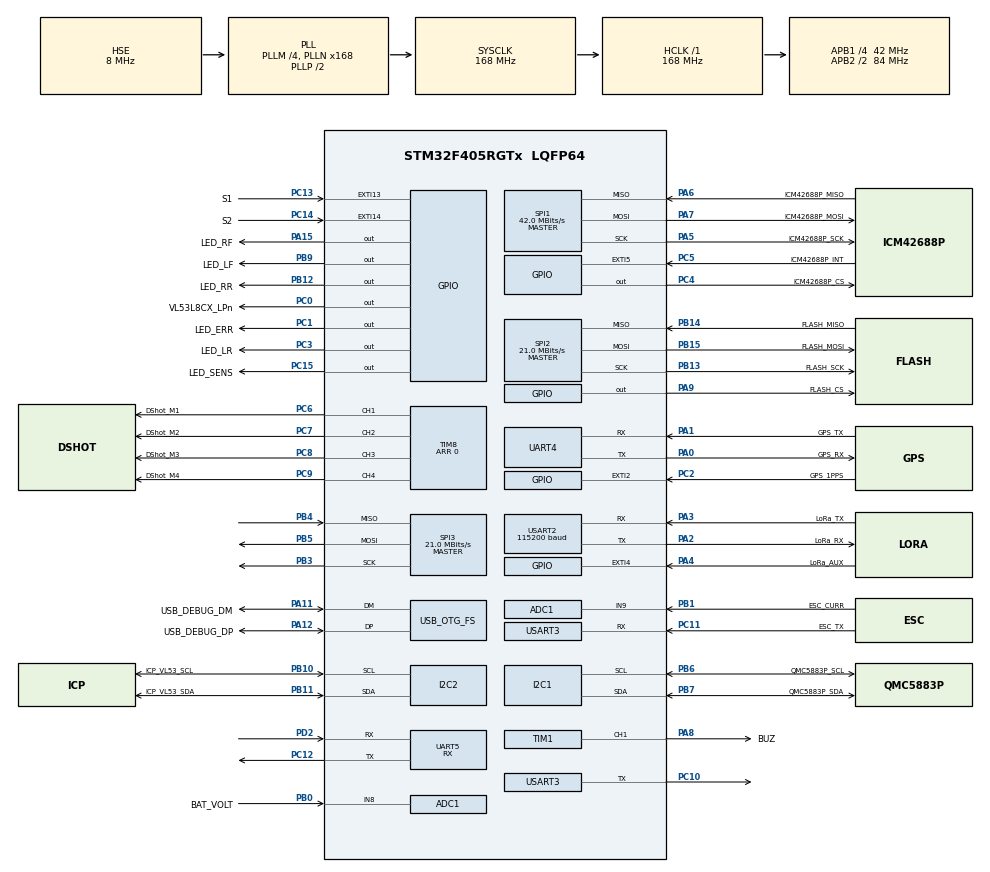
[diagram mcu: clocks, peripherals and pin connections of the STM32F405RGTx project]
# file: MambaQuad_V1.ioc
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ADC1.Channel-0\#ChannelRegularConversion=ADC_CHANNEL_8
ADC1.NbrOfConversionFlag=1
ADC1.Rank-0\#ChannelRegularConversion=1
ADC1.SamplingTime-0\#ChannelRegularConversion=ADC_SAMPLETIME_3CYCLES
ADC1.master=1
Dma.Request0=TIM8_CH1
Dma.Request1=TIM8_CH2
Dma.Request2=TIM8_CH3
Dma.Request3=TIM8_CH4/TRIG/COM
Dma.Request4=UART4_RX
Dma.Request5=UART5_RX
Dma.Request6=USART2_RX
Dma.Request7=USART3_RX
Dma.TIM8_CH1.0.Direction=DMA_MEMORY_TO_PERIPH
Dma.TIM8_CH1.0.FIFOMode=DMA_FIFOMODE_ENABLE
Dma.TIM8_CH1.0.FIFOThreshold=DMA_FIFO_THRESHOLD_1QUARTERFULL
Dma.TIM8_CH1.0.Instance=DMA2_Stream2
Dma.TIM8_CH1.0.MemBurst=DMA_MBURST_SINGLE
Dma.TIM8_CH1.0.MemDataAlignment=DMA_MDATAALIGN_WORD
Dma.TIM8_CH1.0.MemInc=DMA_MINC_ENABLE
Dma.TIM8_CH1.0.Mode=DMA_NORMAL
Dma.TIM8_CH1.0.PeriphBurst=DMA_PBURST_SINGLE
Dma.TIM8_CH1.0.PeriphDataAlignment=DMA_PDATAALIGN_WORD
Dma.TIM8_CH1.0.PeriphInc=DMA_PINC_DISABLE
Dma.TIM8_CH1.0.Priority=DMA_PRIORITY_HIGH
Dma.TIM8_CH2.1.Direction=DMA_MEMORY_TO_PERIPH
Dma.TIM8_CH2.1.FIFOMode=DMA_FIFOMODE_ENABLE
Dma.TIM8_CH2.1.FIFOThreshold=DMA_FIFO_THRESHOLD_1QUARTERFULL
Dma.TIM8_CH2.1.Instance=DMA2_Stream3
Dma.TIM8_CH2.1.MemBurst=DMA_MBURST_SINGLE
Dma.TIM8_CH2.1.MemDataAlignment=DMA_MDATAALIGN_WORD
Dma.TIM8_CH2.1.MemInc=DMA_MINC_ENABLE
Dma.TIM8_CH2.1.Mode=DMA_NORMAL
Dma.TIM8_CH2.1.PeriphBurst=DMA_PBURST_SINGLE
Dma.TIM8_CH2.1.PeriphDataAlignment=DMA_PDATAALIGN_WORD
Dma.TIM8_CH2.1.PeriphInc=DMA_PINC_DISABLE
Dma.TIM8_CH2.1.Priority=DMA_PRIORITY_HIGH
Dma.TIM8_CH3.2.Direction=DMA_MEMORY_TO_PERIPH
Dma.TIM8_CH3.2.FIFOMode=DMA_FIFOMODE_ENABLE
Dma.TIM8_CH3.2.FIFOThreshold=DMA_FIFO_THRESHOLD_1QUARTERFULL
Dma.TIM8_CH3.2.Instance=DMA2_Stream4
Dma.TIM8_CH3.2.MemBurst=DMA_MBURST_SINGLE
Dma.TIM8_CH3.2.MemDataAlignment=DMA_MDATAALIGN_WORD
Dma.TIM8_CH3.2.MemInc=DMA_MINC_ENABLE
Dma.TIM8_CH3.2.Mode=DMA_NORMAL
Dma.TIM8_CH3.2.PeriphBurst=DMA_PBURST_SINGLE
Dma.TIM8_CH3.2.PeriphDataAlignment=DMA_PDATAALIGN_WORD
Dma.TIM8_CH3.2.PeriphInc=DMA_PINC_DISABLE
Dma.TIM8_CH3.2.Priority=DMA_PRIORITY_HIGH
Dma.TIM8_CH4/TRIG/COM.3.Direction=DMA_MEMORY_TO_PERIPH
Dma.TIM8_CH4/TRIG/COM.3.FIFOMode=DMA_FIFOMODE_ENABLE
Dma.TIM8_CH4/TRIG/COM.3.FIFOThreshold=DMA_FIFO_THRESHOLD_1QUARTERFULL
Dma.TIM8_CH4/TRIG/COM.3.Instance=DMA2_Stream7
Dma.TIM8_CH4/TRIG/COM.3.MemBurst=DMA_MBURST_SINGLE
Dma.TIM8_CH4/TRIG/COM.3.MemDataAlignment=DMA_MDATAALIGN_WORD
Dma.TIM8_CH4/TRIG/COM.3.MemInc=DMA_MINC_ENABLE
Dma.TIM8_CH4/TRIG/COM.3.Mode=DMA_NORMAL
Dma.TIM8_CH4/TRIG/COM.3.PeriphBurst=DMA_PBURST_SINGLE
Dma.TIM8_CH4/TRIG/COM.3.PeriphDataAlignment=DMA_PDATAALIGN_WORD
Dma.TIM8_CH4/TRIG/COM.3.PeriphInc=DMA_PINC_DISABLE
Dma.TIM8_CH4/TRIG/COM.3.Priority=DMA_PRIORITY_HIGH
Dma.UART4_RX.4.Direction=DMA_PERIPH_TO_MEMORY
Dma.UART4_RX.4.FIFOMode=DMA_FIFOMODE_DISABLE
Dma.UART4_RX.4.Instance=DMA1_Stream2
Dma.UART4_RX.4.MemDataAlignment=DMA_MDATAALIGN_BYTE
Dma.UART4_RX.4.MemInc=DMA_MINC_ENABLE
Dma.UART4_RX.4.Mode=DMA_NORMAL
Dma.UART4_RX.4.PeriphDataAlignment=DMA_PDATAALIGN_BYTE
Dma.UART4_RX.4.PeriphInc=DMA_PINC_DISABLE
Dma.UART4_RX.4.Priority=DMA_PRIORITY_LOW
Dma.UART5_RX.5.Direction=DMA_PERIPH_TO_MEMORY
Dma.UART5_RX.5.FIFOMode=DMA_FIFOMODE_DISABLE
Dma.UART5_RX.5.Instance=DMA1_Stream0
Dma.UART5_RX.5.MemDataAlignment=DMA_MDATAALIGN_BYTE
Dma.UART5_RX.5.MemInc=DMA_MINC_ENABLE
Dma.UART5_RX.5.Mode=DMA_NORMAL
Dma.UART5_RX.5.PeriphDataAlignment=DMA_PDATAALIGN_BYTE
Dma.UART5_RX.5.PeriphInc=DMA_PINC_DISABLE
Dma.UART5_RX.5.Priority=DMA_PRIORITY_LOW
Dma.USART2_RX.6.Direction=DMA_PERIPH_TO_MEMORY
Dma.USART2_RX.6.FIFOMode=DMA_FIFOMODE_DISABLE
Dma.USART2_RX.6.Instance=DMA1_Stream5
Dma.USART2_RX.6.MemDataAlignment=DMA_MDATAALIGN_BYTE
Dma.USART2_RX.6.MemInc=DMA_MINC_ENABLE
Dma.USART2_RX.6.Mode=DMA_NORMAL
Dma.USART2_RX.6.PeriphDataAlignment=DMA_PDATAALIGN_BYTE
Dma.USART2_RX.6.PeriphInc=DMA_PINC_DISABLE
Dma.USART2_RX.6.Priority=DMA_PRIORITY_LOW
Dma.USART3_RX.7.Direction=DMA_PERIPH_TO_MEMORY
Dma.USART3_RX.7.FIFOMode=DMA_FIFOMODE_DISABLE
Dma.USART3_RX.7.Instance=DMA1_Stream1
Dma.USART3_RX.7.MemDataAlignment=DMA_MDATAALIGN_BYTE
Dma.USART3_RX.7.MemInc=DMA_MINC_ENABLE
Dma.USART3_RX.7.Mode=DMA_NORMAL
Dma.USART3_RX.7.PeriphDataAlignment=DMA_PDATAALIGN_BYTE
Dma.USART3_RX.7.PeriphInc=DMA_PINC_DISABLE
Dma.USART3_RX.7.Priority=DMA_PRIORITY_LOW
Mcu.Family=STM32F4
Mcu.Name=STM32F405RGTx
Mcu.Package=LQFP64
NVIC.DMA1_Stream0_IRQn=true\:5\:0\:true\:false\:true\:false\:true\:true
NVIC.DMA1_Stream1_IRQn=true\:5\:0\:true\:false\:true\:false\:true\:true
NVIC.DMA1_Stream2_IRQn=true\:5\:0\:true\:false\:true\:false\:true\:true
NVIC.DMA1_Stream5_IRQn=true\:5\:0\:true\:false\:true\:false\:true\:true
NVIC.DMA2_Stream2_IRQn=true\:5\:0\:true\:false\:true\:false\:true\:true
NVIC.DMA2_Stream3_IRQn=true\:5\:0\:true\:false\:true\:false\:true\:true
NVIC.DMA2_Stream4_IRQn=true\:5\:0\:true\:false\:true\:false\:true\:true
NVIC.DMA2_Stream7_IRQn=true\:5\:0\:true\:false\:true\:false\:true\:true
NVIC.OTG_FS_IRQn=true\:5\:0\:true\:false\:true\:false\:true\:true
NVIC.PriorityGroup=NVIC_PRIORITYGROUP_4
NVIC.TIM2_IRQn=true\:5\:0\:true\:false\:true\:true\:true\:true
NVIC.TIM7_IRQn=true\:0\:0\:true\:false\:true\:false\:true\:true
NVIC.TimeBase=TIM7_IRQn
NVIC.TimeBaseIP=TIM7
NVIC.UART4_IRQn=true\:5\:0\:true\:false\:true\:true\:true\:true
NVIC.USART2_IRQn=true\:5\:0\:true\:false\:true\:true\:true\:true
PA0-WKUP.GPIO_Label=GPS_RX
PA0-WKUP.Mode=Asynchronous
PA0-WKUP.Signal=UART4_TX
PA1.GPIO_Label=GPS_TX
PA1.Mode=Asynchronous
PA1.Signal=UART4_RX
PA11.GPIO_Label=USB_DEBUG_DM
PA11.Mode=Device_Only
PA11.Signal=USB_OTG_FS_DM
PA12.GPIO_Label=USB_DEBUG_DP
PA12.Mode=Device_Only
PA12.Signal=USB_OTG_FS_DP
PA13.Mode=Serial_Wire
PA13.Signal=SYS_JTMS-SWDIO
PA14.Mode=Serial_Wire
PA14.Signal=SYS_JTCK-SWCLK
PA15.GPIO_Label=LED_RF
PA15.Signal=GPIO_Output
PA2.GPIO_Label=LoRa_RX
PA2.Mode=Asynchronous
PA2.Signal=USART2_TX
PA3.GPIO_Label=LoRa_TX
PA3.Mode=Asynchronous
PA3.Signal=USART2_RX
PA4.GPIO_Label=LoRa_AUX
PA4.Signal=GPXTI4
PA5.GPIO_Label=ICM42688P_SCK
PA5.Mode=Full_Duplex_Master
PA5.Signal=SPI1_SCK
PA6.GPIO_Label=ICM42688P_MISO
PA6.Mode=Full_Duplex_Master
PA6.Signal=SPI1_MISO
PA7.GPIO_Label=ICM42688P_MOSI
PA7.Mode=Full_Duplex_Master
PA7.Signal=SPI1_MOSI
PA8.GPIO_Label=BUZ
PA8.Signal=S_TIM1_CH1
PA9.GPIO_Label=FLASH_CS
PA9.PinState=GPIO_PIN_SET
PA9.Signal=GPIO_Output
PB0.GPIO_Label=BAT_VOLT
PB0.Signal=ADCx_IN8
PB1.GPIO_Label=ESC_CURR
PB1.Signal=ADCx_IN9
PB10.GPIO_Label=ICP_VL53_SCL
PB10.Mode=I2C
PB10.Signal=I2C2_SCL
PB11.GPIO_Label=ICP_VL53_SDA
PB11.Mode=I2C
PB11.Signal=I2C2_SDA
PB12.GPIO_Label=LED_RR
PB12.GPIO_Speed=GPIO_SPEED_FREQ_LOW
PB12.PinState=GPIO_PIN_RESET
PB12.Signal=GPIO_Output
PB13.GPIO_Label=FLASH_SCK
PB13.Mode=Full_Duplex_Master
PB13.Signal=SPI2_SCK
PB14.GPIO_Label=FLASH_MISO
PB14.Mode=Full_Duplex_Master
PB14.Signal=SPI2_MISO
PB15.GPIO_Label=FLASH_MOSI
PB15.Mode=Full_Duplex_Master
PB15.Signal=SPI2_MOSI
PB3.Mode=Full_Duplex_Master
PB3.Signal=SPI3_SCK
PB4.Mode=Full_Duplex_Master
PB4.Signal=SPI3_MISO
PB5.Mode=Full_Duplex_Master
PB5.Signal=SPI3_MOSI
PB6.GPIO_Label=QMC5883P_SCL
PB6.Mode=I2C
PB6.Signal=I2C1_SCL
PB7.GPIO_Label=QMC5883P_SDA
PB7.Mode=I2C
PB7.Signal=I2C1_SDA
PB9.GPIO_Label=LED_LF
PB9.Signal=GPIO_Output
PC0.GPIO_Label=VL53L8CX_LPn
PC0.PinState=GPIO_PIN_RESET
PC0.Signal=GPIO_Output
PC1.GPIO_Label=LED_ERR
PC1.PinState=GPIO_PIN_SET
PC1.Signal=GPIO_Output
PC10.Mode=Asynchronous
PC10.Signal=USART3_TX
PC11.GPIO_Label=ESC_TX
PC11.Mode=Asynchronous
PC11.Signal=USART3_RX
PC12.Mode=Asynchronous
PC12.Signal=UART5_TX
PC13-ANTI_TAMP.GPIO_Label=S1
PC13-ANTI_TAMP.Signal=GPXTI13
PC14-OSC32_IN.GPIO_Label=S2
PC14-OSC32_IN.Signal=GPXTI14
PC15-OSC32_OUT.GPIO_Label=LED_SENS
PC15-OSC32_OUT.PinState=GPIO_PIN_SET
PC15-OSC32_OUT.Signal=GPIO_Output
PC2.GPIO_Label=GPS_1PPS
PC2.Signal=GPXTI2
PC3.GPIO_Label=LED_LR
PC3.Signal=GPIO_Output
PC4.GPIO_Label=ICM42688P_CS
PC4.Signal=GPIO_Output
PC5.GPIO_Label=ICM42688P_INT
PC5.Signal=GPXTI5
PC6.GPIO_Label=DShot_M1
PC6.GPIO_Speed=GPIO_SPEED_FREQ_HIGH
PC6.Signal=S_TIM8_CH1
PC7.GPIO_Label=DShot_M2
PC7.GPIO_Speed=GPIO_SPEED_FREQ_HIGH
PC7.Signal=S_TIM8_CH2
PC8.GPIO_Label=DShot_M3
PC8.GPIO_Speed=GPIO_SPEED_FREQ_HIGH
PC8.Signal=S_TIM8_CH3
PC9.GPIO_Label=DShot_M4
PC9.GPIO_Speed=GPIO_SPEED_FREQ_HIGH
PC9.Signal=S_TIM8_CH4
PD2.Mode=Asynchronous
PD2.Signal=UART5_RX
PH0-OSC_IN.Mode=HSE-External-Oscillator
PH0-OSC_IN.Signal=RCC_OSC_IN
PH1-OSC_OUT.Mode=HSE-External-Oscillator
PH1-OSC_OUT.Signal=RCC_OSC_OUT
ProjectManager.HeapSize=0x200
ProjectManager.StackSize=0x400
ProjectManager.TargetToolchain=Makefile
RCC.48MHZClocksFreq_Value=48000000
RCC.AHBFreq_Value=168000000
RCC.APB1CLKDivider=RCC_HCLK_DIV4
RCC.APB1Freq_Value=42000000
RCC.APB1TimFreq_Value=84000000
RCC.APB2CLKDivider=RCC_HCLK_DIV2
RCC.APB2Freq_Value=84000000
RCC.APB2TimFreq_Value=168000000
RCC.CortexFreq_Value=168000000
RCC.HCLKFreq_Value=168000000
RCC.HSE_VALUE=8000000
RCC.HSI_VALUE=16000000
RCC.LSE_VALUE=32768
RCC.PLLM=4
RCC.PLLN=168
RCC.PLLQ=7
RCC.SYSCLKFreq_VALUE=168000000
RCC.SYSCLKSource=RCC_SYSCLKSOURCE_PLLCLK
RCC.VCOOutputFreq_Value=336000000
SH.ADCx_IN8.0=ADC1_IN8,IN8
SH.ADCx_IN8.1=ADC2_IN8
SH.ADCx_IN9.0=ADC1_IN9,IN9
SH.S_TIM1_CH1.0=TIM1_CH1,PWM Generation1 CH1
SH.S_TIM8_CH1.0=TIM8_CH1,PWM Generation1 CH1
SH.S_TIM8_CH2.0=TIM8_CH2,PWM Generation2 CH2
SH.S_TIM8_CH3.0=TIM8_CH3,PWM Generation3 CH3
SH.S_TIM8_CH4.0=TIM8_CH4,PWM Generation4 CH4
SPI1.CalculateBaudRate=42.0 MBits/s
SPI1.Direction=SPI_DIRECTION_2LINES
SPI1.Mode=SPI_MODE_MASTER
SPI1.VirtualType=VM_MASTER
SPI2.BaudRatePrescaler=SPI_BAUDRATEPRESCALER_2
SPI2.CalculateBaudRate=21.0 MBits/s
SPI2.Direction=SPI_DIRECTION_2LINES
SPI2.Mode=SPI_MODE_MASTER
SPI2.VirtualType=VM_MASTER
SPI3.BaudRatePrescaler=SPI_BAUDRATEPRESCALER_2
SPI3.CalculateBaudRate=21.0 MBits/s
SPI3.Direction=SPI_DIRECTION_2LINES
SPI3.Mode=SPI_MODE_MASTER
SPI3.VirtualType=VM_MASTER
TIM1.AutoReloadPreload=TIM_AUTORELOAD_PRELOAD_ENABLE
TIM1.Channel-PWM\ Generation1\ CH1=TIM_CHANNEL_1
TIM1.Period=1000 - 1
TIM1.Prescaler=168 - 1
TIM2.AutoReloadPreload=TIM_AUTORELOAD_PRELOAD_ENABLE
TIM2.Period=250 - 1
TIM2.Prescaler=84 - 1
TIM8.Channel-PWM\ Generation1\ CH1=TIM_CHANNEL_1
TIM8.Channel-PWM\ Generation2\ CH2=TIM_CHANNEL_2
TIM8.Channel-PWM\ Generation3\ CH3=TIM_CHANNEL_3
TIM8.Channel-PWM\ Generation4\ CH4=TIM_CHANNEL_4
TIM8.OCFastMode_PWM-PWM\ Generation1\ CH1=TIM_OCFAST_ENABLE
TIM8.OCFastMode_PWM-PWM\ Generation2\ CH2=TIM_OCFAST_ENABLE
TIM8.OCFastMode_PWM-PWM\ Generation3\ CH3=TIM_OCFAST_ENABLE
TIM8.OCFastMode_PWM-PWM\ Generation4\ CH4=TIM_OCFAST_ENABLE
TIM8.Period=0
UART4.VirtualMode=Asynchronous
UART5.Mode=MODE_RX
UART5.VirtualMode=Asynchronous
USART2.BaudRate=115200
USART2.VirtualMode=VM_ASYNC
USART3.VirtualMode=VM_ASYNC
USB_DEVICE.CLASS_NAME_FS=CDC
USB_DEVICE.VirtualMode-CDC_FS=Cdc
USB_DEVICE.VirtualModeFS=Cdc_FS
USB_OTG_FS.VirtualMode=Device_Only
VP_SYS_VS_tim7.Mode=TIM7
VP_TIM2_VS_ClockSourceINT.Mode=Internal
VP_USB_DEVICE_VS_USB_DEVICE_CDC_FS.Mode=CDC_FS
board=custom

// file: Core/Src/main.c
/* USER CODE BEGIN Header */
/**
  ******************************************************************************
  * @file           : main.c
  * @brief          : Main program body
  ******************************************************************************
  * @attention
  *
  * Copyright (c) 2026 STMicroelectronics.
  * All rights reserved.
  *
  * This software is licensed under terms that can be found in the LICENSE file
  * in the root directory of this software component.
  * If no LICENSE file comes with this software, it is provided AS-IS.
  *
  ******************************************************************************
  */
/* USER CODE END Header */
#include "main.h"
#include "adc.h"
#include "dma.h"
#include "i2c.h"
#include "spi.h"
#include "tim.h"
#include "usart.h"
#include "usb_device.h"
#include "gpio.h"

/* USER CODE BEGIN Includes */
#include "cpp_main.h"
extern void xPortSysTickHandler( void );
/* USER CODE END Includes */

void SystemClock_Config(void);

int main(void)
{

  /* MCU Configuration--------------------------------------------------------*/

  /* Reset of all peripherals, Initializes the Flash interface and the Systick. */
  HAL_Init();

  /* Configure the system clock */
  SystemClock_Config();

  /* USER CODE BEGIN SysInit */
  HAL_Delay(1);
  /* USER CODE END SysInit */

  /* Initialize all configured peripherals */
  MX_GPIO_Init();
  MX_DMA_Init();
  MX_I2C1_Init();
  MX_SPI1_Init();
  MX_UART4_Init();
  MX_UART5_Init();
  MX_USART3_UART_Init();
  MX_TIM8_Init();
  MX_I2C2_Init();
  MX_SPI3_Init();
  MX_USART2_UART_Init();
  MX_ADC1_Init();
  MX_USB_DEVICE_Init();
  MX_SPI2_Init();
  MX_TIM1_Init();
  MX_TIM2_Init();
  /* USER CODE BEGIN 2 */
	cpp_main();
  /* USER CODE END 2 */

  /* Infinite loop */
  while (1)
  {

  }
}

void SystemClock_Config(void)
{
  RCC_OscInitTypeDef RCC_OscInitStruct = {0};
  RCC_ClkInitTypeDef RCC_ClkInitStruct = {0};

  /** Configure the main internal regulator output voltage
  */
  __HAL_RCC_PWR_CLK_ENABLE();
  __HAL_PWR_VOLTAGESCALING_CONFIG(PWR_REGULATOR_VOLTAGE_SCALE1);

  /** Initializes the RCC Oscillators according to the specified parameters
  * in the RCC_OscInitTypeDef structure.
  */
  RCC_OscInitStruct.OscillatorType = RCC_OSCILLATORTYPE_HSE;
  RCC_OscInitStruct.HSEState = RCC_HSE_ON;
  RCC_OscInitStruct.PLL.PLLState = RCC_PLL_ON;
  RCC_OscInitStruct.PLL.PLLSource = RCC_PLLSOURCE_HSE;
  RCC_OscInitStruct.PLL.PLLM = 4;
  RCC_OscInitStruct.PLL.PLLN = 168;
  RCC_OscInitStruct.PLL.PLLP = RCC_PLLP_DIV2;
  RCC_OscInitStruct.PLL.PLLQ = 7;
  if (HAL_RCC_OscConfig(&RCC_OscInitStruct) != HAL_OK)
  {
    Error_Handler();
  }

  /** Initializes the CPU, AHB and APB buses clocks
  */
  RCC_ClkInitStruct.ClockType = RCC_CLOCKTYPE_HCLK|RCC_CLOCKTYPE_SYSCLK
                              |RCC_CLOCKTYPE_PCLK1|RCC_CLOCKTYPE_PCLK2;
  RCC_ClkInitStruct.SYSCLKSource = RCC_SYSCLKSOURCE_PLLCLK;
  RCC_ClkInitStruct.AHBCLKDivider = RCC_SYSCLK_DIV1;
  RCC_ClkInitStruct.APB1CLKDivider = RCC_HCLK_DIV4;
  RCC_ClkInitStruct.APB2CLKDivider = RCC_HCLK_DIV2;

  if (HAL_RCC_ClockConfig(&RCC_ClkInitStruct, FLASH_LATENCY_5) != HAL_OK)
  {
    Error_Handler();
  }
}

void HAL_TIM_PeriodElapsedCallback(TIM_HandleTypeDef *htim)
{
  /* USER CODE BEGIN Callback 0 */
  if (htim->Instance == TIM2) {
      dshot_send_all(); // 1ms period for each motor
  }
  /* USER CODE END Callback 0 */
  if (htim->Instance == TIM7)
  {
    HAL_IncTick();
  }
}

void Error_Handler(void)
{
  __disable_irq();
  while (1)
  {
  }
}
